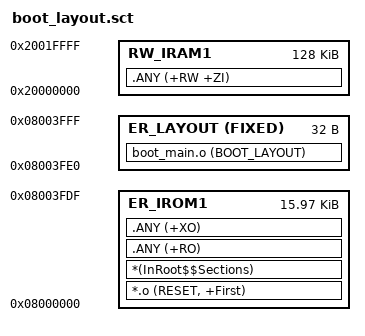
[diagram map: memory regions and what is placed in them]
; Keep initialized RAM data before the fixed layout descriptor in Sector 0.
LR_IROM1 0x08000000 0x00004000 {
  ER_IROM1 0x08000000 0x00003FE0 {
    *.o (RESET, +First)
    *(InRoot$$Sections)
    .ANY (+RO)
    .ANY (+XO)
  }
  RW_IRAM1 0x20000000 0x00020000 {
    .ANY (+RW +ZI)
  }
  ER_LAYOUT 0x08003FE0 FIXED 0x00000020 {
    boot_main.o (BOOT_LAYOUT)
  }
}
